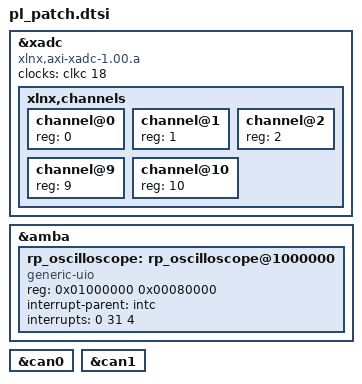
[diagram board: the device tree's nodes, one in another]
/*
 * Zynq XADC configuration
*/

&xadc {
        compatible = "xlnx,axi-xadc-1.00.a";
        clocks = <&clkc 18>;
        xlnx,channels {
                #address-cells = <1>;
                #size-cells = <0>;
                channel@0 {
                        reg = <0>;
                };
                channel@1 {
                        reg = <1>;
                };
                channel@2 {
                        reg = <2>;
                };
                channel@9 {
                        reg = <9>;
                };
                channel@10 {
                        reg = <10>;
                };
        };
};

&amba {
        rp_oscilloscope: rp_oscilloscope@1000000 {
                compatible = "generic-uio", "xlnx,rp-oscilloscope-1.16";
                /*
                 * Keep the dedicated IRQ UIO separate from the legacy
                 * api@40000000 device to avoid overlapping reg resources.
                 * Userspace still accesses scope control registers via
                 * /dev/uio0 and waits for interrupts on this dedicated
                 * oscilloscope /dev/uio1 node.
                 */
                reg = <0x01000000 0x00080000>;
                reg-names = "buffer";
                interrupt-names = "intr";
                interrupt-parent = <&intc>;
                interrupts = <0 31 4>;
                status = "okay";
        };
};

/ {
         fragment@9 {
                target = <&can0>;
                overlay9: __overlay__ {
                        status = "okay";
                };
        };

        fragment@10 {
                target = <&can1>;
                overlay10: __overlay__ {
                        status = "okay";
                };
        };
};
